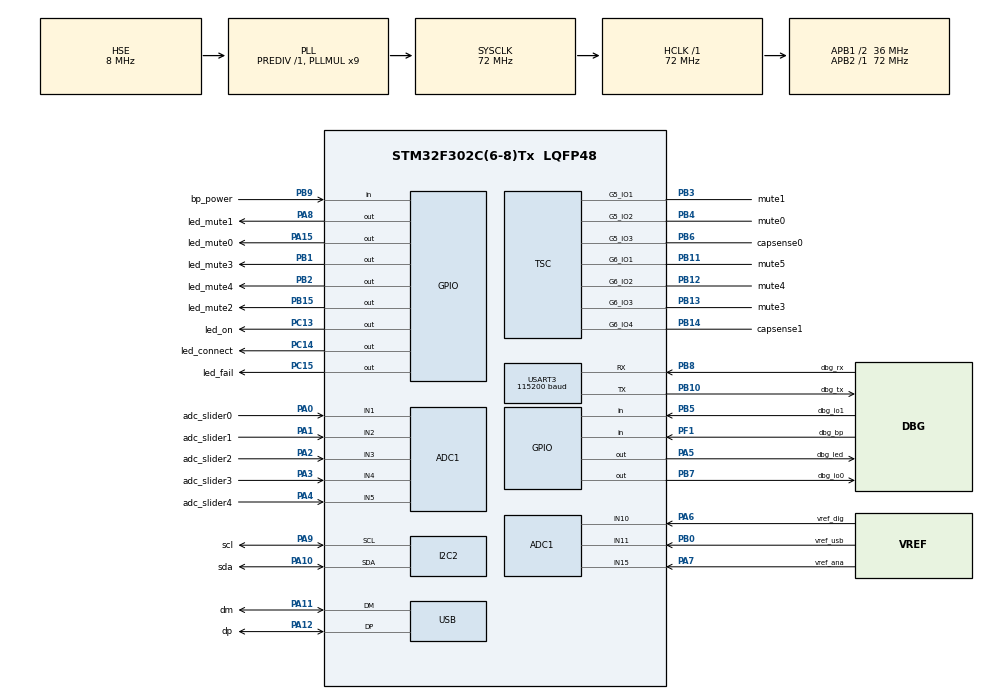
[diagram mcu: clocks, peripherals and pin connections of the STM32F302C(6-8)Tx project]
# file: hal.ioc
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ADC1.Channel-0\#ChannelRegularConversion=ADC_CHANNEL_1
ADC1.NbrOfConversionFlag=1
ADC1.Offset-0\#ChannelRegularConversion=0
ADC1.OffsetNumber-0\#ChannelRegularConversion=ADC_OFFSET_NONE
ADC1.Rank-0\#ChannelRegularConversion=1
ADC1.SamplingTime-0\#ChannelRegularConversion=ADC_SAMPLETIME_1CYCLE_5
ADC1.SubFamily=STM32F302x8
ADC1.master=1
I2C2.Timing=0x00201D2B
Mcu.Family=STM32F3
Mcu.Name=STM32F302C(6-8)Tx
Mcu.Package=LQFP48
NVIC.PriorityGroup=NVIC_PRIORITYGROUP_4
PA0.GPIO_Label=adc_slider0
PA0.Mode=IN1-Single-Ended
PA0.Signal=ADC1_IN1
PA1.GPIO_Label=adc_slider1
PA1.Mode=IN2-Single-Ended
PA1.Signal=ADC1_IN2
PA10.GPIO_Label=sda
PA10.Mode=I2C
PA10.Signal=I2C2_SDA
PA11.GPIO_Label=dm
PA11.Mode=Device
PA11.Signal=USB_DM
PA12.GPIO_Label=dp
PA12.Mode=Device
PA12.Signal=USB_DP
PA13.GPIO_Label=swdio
PA13.Mode=Serial_Wire
PA13.Signal=SYS_JTMS-SWDIO
PA14.GPIO_Label=swclk
PA14.Mode=Serial_Wire
PA14.Signal=SYS_JTCK-SWCLK
PA15.GPIO_Label=led_mute0
PA15.Signal=GPIO_Output
PA2.GPIO_Label=adc_slider2
PA2.Mode=IN3-Single-Ended
PA2.Signal=ADC1_IN3
PA3.GPIO_Label=adc_slider3
PA3.Mode=IN4-Single-Ended
PA3.Signal=ADC1_IN4
PA4.GPIO_Label=adc_slider4
PA4.Mode=IN5-Single-Ended
PA4.Signal=ADC1_IN5
PA5.GPIO_Label=dbg_led
PA5.Signal=GPIO_Output
PA6.GPIO_Label=vref_dig
PA6.Signal=ADCx_IN10
PA7.GPIO_Label=vref_ana
PA7.Mode=IN15-Single-Ended
PA7.Signal=ADC1_IN15
PA8.GPIO_Label=led_mute1
PA8.Signal=GPIO_Output
PA9.GPIO_Label=scl
PA9.Mode=I2C
PA9.Signal=I2C2_SCL
PB0.GPIO_Label=vref_usb
PB0.Mode=IN11-Single-Ended
PB0.Signal=ADC1_IN11
PB1.GPIO_Label=led_mute3
PB1.Signal=GPIO_Output
PB10.GPIO_Label=dbg_tx
PB10.Mode=Asynchronous
PB10.Signal=USART3_TX
PB11.GPIO_Label=mute5
PB11.Mode=G6_IO1-Channel
PB11.Signal=TSC_G6_IO1
PB12.GPIO_Label=mute4
PB12.Mode=G6_IO2-Channel
PB12.Signal=TSC_G6_IO2
PB13.GPIO_Label=mute3
PB13.Mode=G6_IO3-Channel
PB13.Signal=TSC_G6_IO3
PB14.GPIO_Label=capsense1
PB14.Mode=G6_IO4-Sampling
PB14.Signal=TSC_G6_IO4
PB15.GPIO_Label=led_mute2
PB15.Signal=GPIO_Output
PB2.GPIO_Label=led_mute4
PB2.Signal=GPIO_Output
PB3.GPIO_Label=mute1
PB3.Mode=G5_IO1-Channel
PB3.Signal=TSC_G5_IO1
PB4.GPIO_Label=mute0
PB4.Mode=G5_IO2-Channel
PB4.Signal=TSC_G5_IO2
PB5.GPIO_Label=dbg_io1
PB5.Signal=GPIO_Input
PB6.GPIO_Label=capsense0
PB6.Mode=G5_IO3-Sampling
PB6.Signal=TSC_G5_IO3
PB7.GPIO_Label=dbg_io0
PB7.Signal=GPIO_Output
PB8.GPIO_Label=dbg_rx
PB8.Mode=Asynchronous
PB8.Signal=USART3_RX
PB9.GPIO_Label=bp_power
PB9.Signal=GPIO_Input
PC13.GPIO_Label=led_on
PC13.Signal=GPIO_Output
PC14\ -\ OSC32_IN.GPIO_Label=led_connect
PC14\ -\ OSC32_IN.Signal=GPIO_Output
PC15\ -\ OSC32_OUT.GPIO_Label=led_fail
PC15\ -\ OSC32_OUT.Signal=GPIO_Output
PF0-OSC_IN.Mode=HSE-External-Clock-Source
PF0-OSC_IN.Signal=RCC_OSC_IN
PF1-OSC_OUT.GPIO_Label=dbg_bp
PF1-OSC_OUT.Signal=GPIO_Input
ProjectManager.HeapSize=0x200
ProjectManager.StackSize=0x400
ProjectManager.TargetToolchain=STM32CubeIDE
RCC.AHBFreq_Value=72000000
RCC.APB1CLKDivider=RCC_HCLK_DIV2
RCC.APB1Freq_Value=36000000
RCC.APB1TimFreq_Value=72000000
RCC.APB2Freq_Value=72000000
RCC.APB2TimFreq_Value=72000000
RCC.CortexFreq_Value=72000000
RCC.EnbaleCSS=true
RCC.HCLKFreq_Value=72000000
RCC.HSE_VALUE=8000000
RCC.HSI_VALUE=8000000
RCC.LSE_VALUE=32768
RCC.PLLMUL=RCC_PLL_MUL9
RCC.PRESCALERUSB=RCC_USBCLKSOURCE_PLL_DIV1_5
RCC.SYSCLKFreq_VALUE=72000000
RCC.SYSCLKSourceVirtual=RCC_SYSCLKSOURCE_PLLCLK
RCC.USBFreq_Value=48000000
SH.ADCx_IN10.0=ADC1_IN10,IN10-Single-Ended
TSC.ChannelIOs-G5_IO1=TSC_GROUP5_IO1
TSC.ChannelIOs-G5_IO2=TSC_GROUP5_IO2
TSC.ChannelIOs-G6_IO1=TSC_GROUP6_IO1
TSC.ChannelIOs-G6_IO2=TSC_GROUP6_IO2
TSC.ChannelIOs-G6_IO3=TSC_GROUP6_IO3
TSC.SamplingIOs-G5_IO3=TSC_GROUP5_IO3
TSC.SamplingIOs-G6_IO4=TSC_GROUP6_IO4
USART3.BaudRate=115200
USART3.VirtualMode-Asynchronous=VM_ASYNC
VP_ADC1_TempSens_Input.Mode=IN-TempSens
VP_ADC1_Vbat_Input.Mode=IN-Vbat
VP_ADC1_Vref_Input.Mode=IN-Vrefint
board=custom

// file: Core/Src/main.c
/* USER CODE BEGIN Header */
/**
  ******************************************************************************
  * @file           : main.c
  * @brief          : Main program body
  ******************************************************************************
  * @attention
  *
  * Copyright (c) 2025 STMicroelectronics.
  * All rights reserved.
  *
  * This software is licensed under terms that can be found in the LICENSE file
  * in the root directory of this software component.
  * If no LICENSE file comes with this software, it is provided AS-IS.
  *
  ******************************************************************************
  */
/* USER CODE END Header */
#include "main.h"

ADC_HandleTypeDef hadc1;

I2C_HandleTypeDef hi2c2;

TSC_HandleTypeDef htsc;

UART_HandleTypeDef huart3;

PCD_HandleTypeDef hpcd_USB_FS;

void SystemClock_Config(void);
static void MX_GPIO_Init(void);
static void MX_ADC1_Init(void);
static void MX_I2C2_Init(void);
static void MX_TSC_Init(void);
static void MX_USART3_UART_Init(void);
static void MX_USB_PCD_Init(void);

int main(void)
{

  /* MCU Configuration--------------------------------------------------------*/

  /* Reset of all peripherals, Initializes the Flash interface and the Systick. */
  HAL_Init();

  /* Configure the system clock */
  SystemClock_Config();

  /* Initialize all configured peripherals */
  MX_GPIO_Init();
  MX_ADC1_Init();
  MX_I2C2_Init();
  MX_TSC_Init();
  MX_USART3_UART_Init();
  MX_USB_PCD_Init();

  /* Infinite loop */
  /* USER CODE BEGIN WHILE */
  const uint8_t *data = (uint8_t*)"Hello World !\r\n";

  while (1)
  {
    /* USER CODE END WHILE */

    /* USER CODE BEGIN 3 */

	  HAL_UART_Transmit(&huart3, data, 15, 100);
	  HAL_Delay(1000);
  }
  /* USER CODE END 3 */
}

void SystemClock_Config(void)
{
  RCC_OscInitTypeDef RCC_OscInitStruct = {0};
  RCC_ClkInitTypeDef RCC_ClkInitStruct = {0};
  RCC_PeriphCLKInitTypeDef PeriphClkInit = {0};

  /** Initializes the RCC Oscillators according to the specified parameters
  * in the RCC_OscInitTypeDef structure.
  */
  RCC_OscInitStruct.OscillatorType = RCC_OSCILLATORTYPE_HSI|RCC_OSCILLATORTYPE_HSE;
  RCC_OscInitStruct.HSEState = RCC_HSE_BYPASS;
  RCC_OscInitStruct.HSEPredivValue = RCC_HSE_PREDIV_DIV1;
  RCC_OscInitStruct.HSIState = RCC_HSI_ON;
  RCC_OscInitStruct.HSICalibrationValue = RCC_HSICALIBRATION_DEFAULT;
  RCC_OscInitStruct.PLL.PLLState = RCC_PLL_ON;
  RCC_OscInitStruct.PLL.PLLSource = RCC_PLLSOURCE_HSE;
  RCC_OscInitStruct.PLL.PLLMUL = RCC_PLL_MUL9;
  if (HAL_RCC_OscConfig(&RCC_OscInitStruct) != HAL_OK)
  {
    Error_Handler();
  }

  /** Initializes the CPU, AHB and APB buses clocks
  */
  RCC_ClkInitStruct.ClockType = RCC_CLOCKTYPE_HCLK|RCC_CLOCKTYPE_SYSCLK
                              |RCC_CLOCKTYPE_PCLK1|RCC_CLOCKTYPE_PCLK2;
  RCC_ClkInitStruct.SYSCLKSource = RCC_SYSCLKSOURCE_PLLCLK;
  RCC_ClkInitStruct.AHBCLKDivider = RCC_SYSCLK_DIV1;
  RCC_ClkInitStruct.APB1CLKDivider = RCC_HCLK_DIV2;
  RCC_ClkInitStruct.APB2CLKDivider = RCC_HCLK_DIV1;

  if (HAL_RCC_ClockConfig(&RCC_ClkInitStruct, FLASH_LATENCY_2) != HAL_OK)
  {
    Error_Handler();
  }
  PeriphClkInit.PeriphClockSelection = RCC_PERIPHCLK_USB|RCC_PERIPHCLK_I2C2
                              |RCC_PERIPHCLK_ADC1;
  PeriphClkInit.I2c2ClockSelection = RCC_I2C2CLKSOURCE_HSI;
  PeriphClkInit.USBClockSelection = RCC_USBCLKSOURCE_PLL_DIV1_5;
  PeriphClkInit.Adc1ClockSelection = RCC_ADC1PLLCLK_DIV1;

  if (HAL_RCCEx_PeriphCLKConfig(&PeriphClkInit) != HAL_OK)
  {
    Error_Handler();
  }

  /** Enables the Clock Security System
  */
  HAL_RCC_EnableCSS();
}

static void MX_ADC1_Init(void)
{

  ADC_ChannelConfTypeDef sConfig = {0};

  /** Common config
  */
  hadc1.Instance = ADC1;
  hadc1.Init.ClockPrescaler = ADC_CLOCK_ASYNC_DIV1;
  hadc1.Init.Resolution = ADC_RESOLUTION_12B;
  hadc1.Init.ScanConvMode = ADC_SCAN_DISABLE;
  hadc1.Init.ContinuousConvMode = DISABLE;
  hadc1.Init.DiscontinuousConvMode = DISABLE;
  hadc1.Init.ExternalTrigConvEdge = ADC_EXTERNALTRIGCONVEDGE_NONE;
  hadc1.Init.ExternalTrigConv = ADC_SOFTWARE_START;
  hadc1.Init.DataAlign = ADC_DATAALIGN_RIGHT;
  hadc1.Init.NbrOfConversion = 1;
  hadc1.Init.DMAContinuousRequests = DISABLE;
  hadc1.Init.EOCSelection = ADC_EOC_SINGLE_CONV;
  hadc1.Init.LowPowerAutoWait = DISABLE;
  hadc1.Init.Overrun = ADC_OVR_DATA_OVERWRITTEN;
  if (HAL_ADC_Init(&hadc1) != HAL_OK)
  {
    Error_Handler();
  }

  /** Configure Regular Channel
  */
  sConfig.Channel = ADC_CHANNEL_1;
  sConfig.Rank = ADC_REGULAR_RANK_1;
  sConfig.SingleDiff = ADC_SINGLE_ENDED;
  sConfig.SamplingTime = ADC_SAMPLETIME_1CYCLE_5;
  sConfig.OffsetNumber = ADC_OFFSET_NONE;
  sConfig.Offset = 0;
  if (HAL_ADC_ConfigChannel(&hadc1, &sConfig) != HAL_OK)
  {
    Error_Handler();
  }

}

static void MX_I2C2_Init(void)
{

  hi2c2.Instance = I2C2;
  hi2c2.Init.Timing = 0x00201D2B;
  hi2c2.Init.OwnAddress1 = 0;
  hi2c2.Init.AddressingMode = I2C_ADDRESSINGMODE_7BIT;
  hi2c2.Init.DualAddressMode = I2C_DUALADDRESS_DISABLE;
  hi2c2.Init.OwnAddress2 = 0;
  hi2c2.Init.OwnAddress2Masks = I2C_OA2_NOMASK;
  hi2c2.Init.GeneralCallMode = I2C_GENERALCALL_DISABLE;
  hi2c2.Init.NoStretchMode = I2C_NOSTRETCH_DISABLE;
  if (HAL_I2C_Init(&hi2c2) != HAL_OK)
  {
    Error_Handler();
  }

  /** Configure Analogue filter
  */
  if (HAL_I2CEx_ConfigAnalogFilter(&hi2c2, I2C_ANALOGFILTER_ENABLE) != HAL_OK)
  {
    Error_Handler();
  }

  /** Configure Digital filter
  */
  if (HAL_I2CEx_ConfigDigitalFilter(&hi2c2, 0) != HAL_OK)
  {
    Error_Handler();
  }

}

static void MX_TSC_Init(void)
{

  /** Configure the TSC peripheral
  */
  htsc.Instance = TSC;
  htsc.Init.CTPulseHighLength = TSC_CTPH_2CYCLES;
  htsc.Init.CTPulseLowLength = TSC_CTPL_2CYCLES;
  htsc.Init.SpreadSpectrum = DISABLE;
  htsc.Init.SpreadSpectrumDeviation = 1;
  htsc.Init.SpreadSpectrumPrescaler = TSC_SS_PRESC_DIV1;
  htsc.Init.PulseGeneratorPrescaler = TSC_PG_PRESC_DIV4;
  htsc.Init.MaxCountValue = TSC_MCV_8191;
  htsc.Init.IODefaultMode = TSC_IODEF_OUT_PP_LOW;
  htsc.Init.SynchroPinPolarity = TSC_SYNC_POLARITY_FALLING;
  htsc.Init.AcquisitionMode = TSC_ACQ_MODE_NORMAL;
  htsc.Init.MaxCountInterrupt = DISABLE;
  htsc.Init.ChannelIOs = TSC_GROUP5_IO1|TSC_GROUP5_IO2|TSC_GROUP6_IO1|TSC_GROUP6_IO2
                    |TSC_GROUP6_IO3;
  htsc.Init.ShieldIOs = 0;
  htsc.Init.SamplingIOs = TSC_GROUP5_IO3|TSC_GROUP6_IO4;
  if (HAL_TSC_Init(&htsc) != HAL_OK)
  {
    Error_Handler();
  }

}

static void MX_USART3_UART_Init(void)
{

  huart3.Instance = USART3;
  huart3.Init.BaudRate = 115200;
  huart3.Init.WordLength = UART_WORDLENGTH_8B;
  huart3.Init.StopBits = UART_STOPBITS_1;
  huart3.Init.Parity = UART_PARITY_NONE;
  huart3.Init.Mode = UART_MODE_TX_RX;
  huart3.Init.HwFlowCtl = UART_HWCONTROL_NONE;
  huart3.Init.OverSampling = UART_OVERSAMPLING_16;
  huart3.Init.OneBitSampling = UART_ONE_BIT_SAMPLE_DISABLE;
  huart3.AdvancedInit.AdvFeatureInit = UART_ADVFEATURE_NO_INIT;
  if (HAL_UART_Init(&huart3) != HAL_OK)
  {
    Error_Handler();
  }

}

static void MX_USB_PCD_Init(void)
{

  hpcd_USB_FS.Instance = USB;
  hpcd_USB_FS.Init.dev_endpoints = 8;
  hpcd_USB_FS.Init.speed = PCD_SPEED_FULL;
  hpcd_USB_FS.Init.phy_itface = PCD_PHY_EMBEDDED;
  hpcd_USB_FS.Init.low_power_enable = DISABLE;
  hpcd_USB_FS.Init.battery_charging_enable = DISABLE;
  if (HAL_PCD_Init(&hpcd_USB_FS) != HAL_OK)
  {
    Error_Handler();
  }

}

static void MX_GPIO_Init(void)
{
  GPIO_InitTypeDef GPIO_InitStruct = {0};

  /* GPIO Ports Clock Enable */
  __HAL_RCC_GPIOC_CLK_ENABLE();
  __HAL_RCC_GPIOF_CLK_ENABLE();
  __HAL_RCC_GPIOA_CLK_ENABLE();
  __HAL_RCC_GPIOB_CLK_ENABLE();

  /*Configure GPIO pin Output Level */
  HAL_GPIO_WritePin(GPIOC, led_on_Pin|led_connect_Pin|led_fail_Pin, GPIO_PIN_RESET);

  /*Configure GPIO pin Output Level */
  HAL_GPIO_WritePin(GPIOA, dbg_led_Pin|led_mute1_Pin|led_mute0_Pin, GPIO_PIN_RESET);

  /*Configure GPIO pin Output Level */
  HAL_GPIO_WritePin(GPIOB, led_mute3_Pin|led_mute4_Pin|led_mute2_Pin|dbg_io0_Pin, GPIO_PIN_RESET);

  /*Configure GPIO pins : led_on_Pin led_connect_Pin led_fail_Pin */
  GPIO_InitStruct.Pin = led_on_Pin|led_connect_Pin|led_fail_Pin;
  GPIO_InitStruct.Mode = GPIO_MODE_OUTPUT_PP;
  GPIO_InitStruct.Pull = GPIO_NOPULL;
  GPIO_InitStruct.Speed = GPIO_SPEED_FREQ_LOW;
  HAL_GPIO_Init(GPIOC, &GPIO_InitStruct);

  /*Configure GPIO pin : dbg_bp_Pin */
  GPIO_InitStruct.Pin = dbg_bp_Pin;
  GPIO_InitStruct.Mode = GPIO_MODE_INPUT;
  GPIO_InitStruct.Pull = GPIO_NOPULL;
  HAL_GPIO_Init(dbg_bp_GPIO_Port, &GPIO_InitStruct);

  /*Configure GPIO pins : dbg_led_Pin led_mute1_Pin led_mute0_Pin */
  GPIO_InitStruct.Pin = dbg_led_Pin|led_mute1_Pin|led_mute0_Pin;
  GPIO_InitStruct.Mode = GPIO_MODE_OUTPUT_PP;
  GPIO_InitStruct.Pull = GPIO_NOPULL;
  GPIO_InitStruct.Speed = GPIO_SPEED_FREQ_LOW;
  HAL_GPIO_Init(GPIOA, &GPIO_InitStruct);

  /*Configure GPIO pins : led_mute3_Pin led_mute4_Pin led_mute2_Pin dbg_io0_Pin */
  GPIO_InitStruct.Pin = led_mute3_Pin|led_mute4_Pin|led_mute2_Pin|dbg_io0_Pin;
  GPIO_InitStruct.Mode = GPIO_MODE_OUTPUT_PP;
  GPIO_InitStruct.Pull = GPIO_NOPULL;
  GPIO_InitStruct.Speed = GPIO_SPEED_FREQ_LOW;
  HAL_GPIO_Init(GPIOB, &GPIO_InitStruct);

  /*Configure GPIO pins : dbg_io1_Pin bp_power_Pin */
  GPIO_InitStruct.Pin = dbg_io1_Pin|bp_power_Pin;
  GPIO_InitStruct.Mode = GPIO_MODE_INPUT;
  GPIO_InitStruct.Pull = GPIO_NOPULL;
  HAL_GPIO_Init(GPIOB, &GPIO_InitStruct);

}

void Error_Handler(void)
{
  __disable_irq();
  while (1)
  {
  }
}
